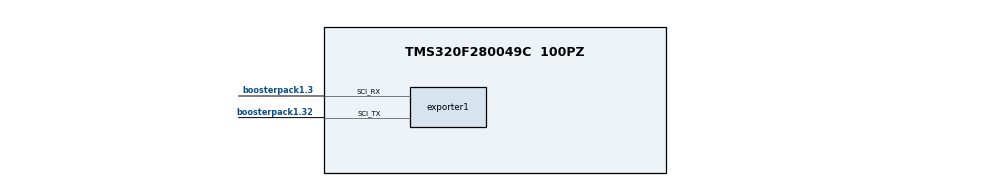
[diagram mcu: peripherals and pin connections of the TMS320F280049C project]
/**
 * These arguments were used when this file was generated. They will be automatically applied on subsequent loads
 * via the GUI or CLI. Run CLI with '--help' for additional information on how to override these arguments.
 * @cliArgs --board "/boards/LAUNCHXL_F280049C" --device "F28004x" --part "F28004x_100PZ" --package "F28004x_100PZ" --context "system" --product "C2000WARE@5.03.00.00"
 * @v2CliArgs --device "TMS320F280049C" --package "100PZ" --board "/boards/LAUNCHXL_F280049C" --context "system" --product "C2000WARE@5.03.00.00"
 * @versions {"tool":"1.21.0+3721"}
 */

/**
 * Import the modules used in this configuration.
 */
const adc            = scripting.addModule("/driverlib/adc.js", {}, false);
const adc1           = adc.addInstance();
const fsi            = scripting.addModule("/driverlib/board_components/fsi", {}, false);
const fsi1           = fsi.addInstance();
const led            = scripting.addModule("/driverlib/board_components/led", {}, false);
const led1           = led.addInstance();
const led2           = led.addInstance();
const clb            = scripting.addModule("/driverlib/clb.js", {}, false);
const clb1           = clb.addInstance();
const dac            = scripting.addModule("/driverlib/dac.js", {}, false);
const dac1           = dac.addInstance();
const device_support = scripting.addModule("/driverlib/device_support.js");
const epwm           = scripting.addModule("/driverlib/epwm.js", {}, false);
const epwm1          = epwm.addInstance();
const epwm2          = epwm.addInstance();
const epwm3          = epwm.addInstance();
const memcfg         = scripting.addModule("/driverlib/memcfg.js");
const spi            = scripting.addModule("/driverlib/spi.js", {}, false);
const spi1           = spi.addInstance();
const FPUfastRTS     = scripting.addModule("/libraries/math/FPUfastRTS/FPUfastRTS.js", {}, false);
const FPUfastRTS1    = FPUfastRTS.addInstance();
const IQmath         = scripting.addModule("/libraries/math/IQmath/IQmath.js", {}, false);
const IQmath1        = IQmath.addInstance();
const exporter       = scripting.addModule("/utilities/transfer/exporter.js", {}, false);
const exporter1      = exporter.addInstance();

/**
 * Write custom configuration values to the imported modules.
 */
adc1.soc8SampleWindow               = 8;
adc1.interruptPulseMode             = "ADC_PULSE_END_OF_CONV";
adc1.enabledInts                    = ["ADC_INT_NUMBER1"];
adc1.enableInterrupt1               = true;
adc1.soc8Trigger                    = "ADC_TRIGGER_EPWM1_SOCA";
adc1.soc8InterruptTrigger           = "ADC_INT_SOC_TRIGGER_ADCINT1";
adc1.$name                          = "ADC_A";
adc1.adcClockPrescaler              = "ADC_CLK_DIV_4_0";
adc1.socHighPriorityMode            = "ADC_PRI_THRU_SOC2_HIPRI";
adc1.enabledSOCs                    = ["ADC_SOC_NUMBER0","ADC_SOC_NUMBER1","ADC_SOC_NUMBER2","ADC_SOC_NUMBER3"];
adc1.soc0Name                       = "Mtr_IU";
adc1.soc0Trigger                    = "ADC_TRIGGER_EPWM1_SOCA";
adc1.soc0SampleWindow               = 8;
adc1.soc0Channel                    = "ADC_CH_ADCIN5";
adc1.soc1Name                       = "Mtr_IV";
adc1.soc1SampleWindow               = 8;
adc1.soc1Trigger                    = "ADC_TRIGGER_EPWM1_SOCA";
adc1.soc2Name                       = "Mtr_IW";
adc1.soc2Channel                    = "ADC_CH_ADCIN3";
adc1.soc2Trigger                    = "ADC_TRIGGER_EPWM1_SOCA";
adc1.soc2SampleWindow               = 8;
adc1.soc3Name                       = "Mtr_VBus";
adc1.soc3SampleWindow               = 8;
adc1.soc3Trigger                    = "ADC_TRIGGER_EPWM1_SOCA";
adc1.soc3Channel                    = "ADC_CH_ADCIN8";
adc1.enableInterrupt1ContinuousMode = true;

fsi1.$name                   = "myBoardFSI0";
fsi1.fsiRx.softwareFrameSize = "16";
fsi1.fsiRx.$hardware         = system.deviceData.board.components.FSI_HEADER;
fsi1.fsiRx.d0Qual.$name      = "myGPIOQUAL4";
fsi1.fsiRx.d1Qual.$name      = "myGPIOQUAL5";
fsi1.fsiRx.clkQual.$name     = "myGPIOQUAL6";
fsi1.fsiTx.$hardware         = system.deviceData.board.components.FSI_HEADER;
fsi1.fsiTx.d0Qual.$name      = "myGPIOQUAL7";
fsi1.fsiTx.d1Qual.$name      = "myGPIOQUAL8";
fsi1.fsiTx.clkQual.$name     = "myGPIOQUAL9";

led1.$name     = "myBoardLED0";
led1.$hardware = system.deviceData.board.components.LED4;

led2.$name     = "myBoardLED1";
led2.$hardware = system.deviceData.board.components.LED5;

clb1.$name = "myCLB0";

dac1.$name        = "myDAC0";
dac1.dacBase      = "DACB_BASE";
dac1.enableOutput = true;

epwm1.$hardware                                                  = system.deviceData.board.components.BP_SITE_1.subComponents.PWM_LOC1;
epwm1.$name                                                      = "EPWMU";
epwm1.epwmTimebase_hsClockDiv                                    = "EPWM_HSCLOCK_DIVIDER_1";
epwm1.epwmTimebase_period                                        = 5000;
epwm1.epwmTimebase_counterMode                                   = "EPWM_COUNTER_MODE_UP_DOWN";
epwm1.epwmTimebase_phaseEnable                                   = true;
epwm1.epwmTimebase_counterModeAfterSync                          = "EPWM_COUNT_MODE_UP_AFTER_SYNC";
epwm1.epwmTimebase_syncOutPulseMode                              = "EPWM_SYNC_OUT_PULSE_ON_COUNTER_ZERO";
epwm1.epwmCounterCompare_cmpA                                    = 2500;
epwm1.epwmCounterCompare_shadowLoadModeCMPA                      = "EPWM_COMP_LOAD_ON_CNTR_ZERO_PERIOD";
epwm1.epwmActionQualifier_EPWM_AQ_OUTPUT_A_ON_TIMEBASE_UP_CMPA   = "EPWM_AQ_OUTPUT_LOW";
epwm1.epwmActionQualifier_EPWM_AQ_OUTPUT_A_ON_TIMEBASE_DOWN_CMPA = "EPWM_AQ_OUTPUT_HIGH";
epwm1.epwmEventTrigger_enableInterrupt                           = true;
epwm1.epwmEventTrigger_EPWM_SOC_A_triggerEnable                  = true;
epwm1.epwmEventTrigger_EPWM_SOC_A_triggerSource                  = "EPWM_SOC_TBCTR_PERIOD";
epwm1.epwmEventTrigger_EPWM_SOC_A_triggerEventPrescalar          = "1";

epwm2.$hardware = system.deviceData.board.components.BP_SITE_1.subComponents.PWM_LOC2;
epwm2.$name     = "EPWMV";

epwm3.$hardware                         = system.deviceData.board.components.BP_SITE_1.subComponents.PWM_LOC3;
epwm3.$name                             = "EPWMW";
epwm3.epwmTimebase_emulationMode        = "EPWM_EMULATION_FREE_RUN";
epwm3.epwmTimebase_hsClockDiv           = "EPWM_HSCLOCK_DIVIDER_1";
epwm3.epwmTimebase_counterMode          = "EPWM_COUNTER_MODE_UP_DOWN";
epwm3.epwmTimebase_counterModeAfterSync = "EPWM_COUNT_MODE_UP_AFTER_SYNC";
epwm3.epwmTimebase_syncOutPulseMode     = "EPWM_SYNC_OUT_PULSE_ON_COUNTER_ZERO";
epwm3.epwmCounterCompare_cmpC           = 5;
epwm3.epwmCounterCompare_cmpD           = 5;
scripting.suppress("CMP value is out of range of TBPRD\\. Refer to table, Behavior if CMPA/CMPB is Greater than the Period, within the TRM", epwm3, "epwmCounterCompare_cmpC");
scripting.suppress("CMP value is out of range of TBPRD\\. Refer to table, Behavior if CMPA/CMPB is Greater than the Period, within the TRM", epwm3, "epwmCounterCompare_cmpD");

spi1.$name          = "mySPI0";
spi1.$hardware      = system.deviceData.board.components.BP_SITE_1.subComponents.SPI;
spi1.mode           = "SPI_MODE_CONTROLLER";
spi1.dataWidth      = "8";
spi1.picoQual.$name = "myGPIOQUAL0";
spi1.pociQual.$name = "myGPIOQUAL1";
spi1.clkQual.$name  = "myGPIOQUAL2";
spi1.pteQual.$name  = "myGPIOQUAL3";

FPUfastRTS1.$name = "myFFR0";

IQmath1.$name = "myIQmath0";

exporter1.$name                                = "myEXPORT0";
exporter1.comsLinkModule.sci.sci_rxPin.$assign = "boosterpack1.3";
exporter1.comsLinkModule.sci.sci_txPin.$assign = "boosterpack1.32";
exporter1.comsLinkModule.rxQual.$name          = "myGPIOQUAL10";
exporter1.comsLinkModule.txQual.$name          = "myGPIOQUAL11";
scripting.suppress("Connected to hardware,@@@.+?@@@ is connected to SCIB BP on the LaunchPad F280049C\\. Consider selecting it in \'use hardware\' above\\. @@@.+?@@@", exporter1.comsLinkModule.sci, "sci_rxPin");

/**
 * Pinmux solution for unlocked pins/peripherals. This ensures that minor changes to the automatic solver in a future
 * version of the tool will not impact the pinmux you originally saw.  These lines can be completely deleted in order to
 * re-solve from scratch.
 */
fsi1.fsiRx.fsirx.$suggestSolution              = "FSIRXA";
fsi1.fsiRx.fsirx.fsirx_d0Pin.$suggestSolution  = "boosterpack2.51";
fsi1.fsiRx.fsirx.fsirx_d1Pin.$suggestSolution  = "boosterpack2.76";
fsi1.fsiRx.fsirx.fsirx_clkPin.$suggestSolution = "boosterpack2.53";
fsi1.fsiTx.fsitx.$suggestSolution              = "FSITXA";
fsi1.fsiTx.fsitx.fsitx_d0Pin.$suggestSolution  = "boosterpack2.78";
fsi1.fsiTx.fsitx.fsitx_d1Pin.$suggestSolution  = "boosterpack1.31";
fsi1.fsiTx.fsitx.fsitx_clkPin.$suggestSolution = "boosterpack2.77";
led1.gpio.gpioPin.$suggestSolution             = "boosterpack1.12";
led2.gpio.gpioPin.$suggestSolution             = "boosterpack2.52";
epwm1.epwm.$suggestSolution                    = "EPWM6";
epwm1.epwm.epwm_aPin.$suggestSolution          = "boosterpack1.40";
epwm1.epwm.epwm_bPin.$suggestSolution          = "boosterpack1.39";
epwm2.epwm.$suggestSolution                    = "EPWM5";
epwm2.epwm.epwm_aPin.$suggestSolution          = "boosterpack1.38";
epwm2.epwm.epwm_bPin.$suggestSolution          = "boosterpack1.37";
epwm3.epwm.$suggestSolution                    = "EPWM3";
epwm3.epwm.epwm_aPin.$suggestSolution          = "boosterpack1.36";
epwm3.epwm.epwm_bPin.$suggestSolution          = "boosterpack1.35";
spi1.spi.$suggestSolution                      = "SPIA";
spi1.spi.spi_picoPin.$suggestSolution          = "boosterpack1.15";
spi1.spi.spi_pociPin.$suggestSolution          = "boosterpack1.14";
spi1.spi.spi_clkPin.$suggestSolution           = "boosterpack1.7";
spi1.spi.spi_ptePin.$suggestSolution           = "boosterpack1.19";
exporter1.comsLinkModule.sci.$suggestSolution  = "SCIB";
